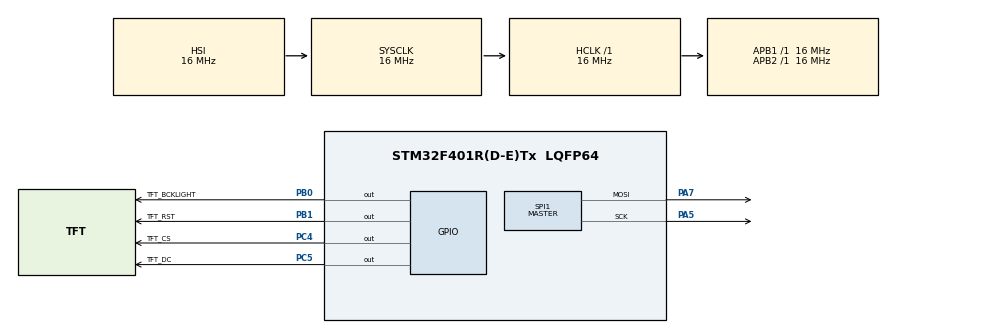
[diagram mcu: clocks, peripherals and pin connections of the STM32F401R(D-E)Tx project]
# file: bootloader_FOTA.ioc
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Mcu.Family=STM32F4
Mcu.Name=STM32F401R(D-E)Tx
Mcu.Package=LQFP64
NVIC.PriorityGroup=NVIC_PRIORITYGROUP_4
PA5.Mode=TX_Only_Simplex_Unidirect_Master
PA5.Signal=SPI1_SCK
PA7.Mode=TX_Only_Simplex_Unidirect_Master
PA7.Signal=SPI1_MOSI
PB0.GPIO_Label=TFT_BCKLIGHT
PB0.Signal=GPIO_Output
PB1.GPIO_Label=TFT_RST
PB1.Signal=GPIO_Output
PC4.GPIO_Label=TFT_CS
PC4.Signal=GPIO_Output
PC5.GPIO_Label=TFT_DC
PC5.Signal=GPIO_Output
ProjectManager.HeapSize=0x200
ProjectManager.StackSize=0x400
ProjectManager.TargetToolchain=Makefile
RCC.AHBFreq_Value=16000000
RCC.APB1Freq_Value=16000000
RCC.APB2Freq_Value=16000000
RCC.CortexFreq_Value=16000000
RCC.HSE_VALUE=25000000
RCC.HSI_VALUE=16000000
RCC.LSE_VALUE=32768
RCC.SYSCLKFreq_VALUE=16000000
RCC.VCOOutputFreq_Value=192000000
SPI1.Direction=SPI_DIRECTION_2LINES
SPI1.Mode=SPI_MODE_MASTER
SPI1.VirtualType=VM_MASTER
VP_CRC_VS_CRC.Mode=CRC_Activate
board=custom

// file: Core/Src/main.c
/* USER CODE BEGIN Header */
/**
  ******************************************************************************
  * @file           : main.c
  * @brief          : Main program body - SPI/ST7789 display test
  ******************************************************************************
  */
/* USER CODE END Header */
#include "main.h"
#include "spi.h"
#include "gpio.h"

/* USER CODE BEGIN Includes */

#include <stdio.h>
#include <stdint.h>

#include "st7789.h"

/* USER CODE END Includes */

void SystemClock_Config(void);

int main(void)
{
  /* Reset of all peripherals, Initializes the Flash interface and the Systick. */
  HAL_Init();

  /* Configure the system clock */
  SystemClock_Config();

  /* Initialize all configured peripherals */
  MX_GPIO_Init();
  MX_SPI1_Init();

  /* USER CODE BEGIN 2 */

  HAL_GPIO_WritePin(TFT_BCKLIGHT_GPIO_Port, TFT_BCKLIGHT_Pin, GPIO_PIN_SET);

  ST7789_Init();

  ST7789_Fill_Color(RED);
  HAL_Delay(1000);
  ST7789_Fill_Color(GREEN);
  HAL_Delay(1000);
  ST7789_Fill_Color(BLUE);
  HAL_Delay(1000);

  /* Run the full built-in test pattern (colors, shapes, text, image) */
  ST7789_Test();

  /* USER CODE END 2 */

  /* Infinite loop */
  while (1)
  {
    /* nothing else to do - test already ran above */
  }
}

void SystemClock_Config(void)
{
  RCC_OscInitTypeDef RCC_OscInitStruct = {0};
  RCC_ClkInitTypeDef RCC_ClkInitStruct = {0};

  __HAL_RCC_PWR_CLK_ENABLE();
  __HAL_PWR_VOLTAGESCALING_CONFIG(PWR_REGULATOR_VOLTAGE_SCALE2);

  RCC_OscInitStruct.OscillatorType = RCC_OSCILLATORTYPE_HSI;
  RCC_OscInitStruct.HSIState = RCC_HSI_ON;
  RCC_OscInitStruct.HSICalibrationValue = RCC_HSICALIBRATION_DEFAULT;
  RCC_OscInitStruct.PLL.PLLState = RCC_PLL_NONE;
  if (HAL_RCC_OscConfig(&RCC_OscInitStruct) != HAL_OK)
  {
    Error_Handler();
  }

  RCC_ClkInitStruct.ClockType = RCC_CLOCKTYPE_HCLK|RCC_CLOCKTYPE_SYSCLK
                              |RCC_CLOCKTYPE_PCLK1|RCC_CLOCKTYPE_PCLK2;
  RCC_ClkInitStruct.SYSCLKSource = RCC_SYSCLKSOURCE_HSI;
  RCC_ClkInitStruct.AHBCLKDivider = RCC_SYSCLK_DIV1;
  RCC_ClkInitStruct.APB1CLKDivider = RCC_HCLK_DIV1;
  RCC_ClkInitStruct.APB2CLKDivider = RCC_HCLK_DIV1;

  if (HAL_RCC_ClockConfig(&RCC_ClkInitStruct, FLASH_LATENCY_0) != HAL_OK)
  {
    Error_Handler();
  }
}

void Error_Handler(void)
{
  __disable_irq();
  while (1)
  {
  }
}
